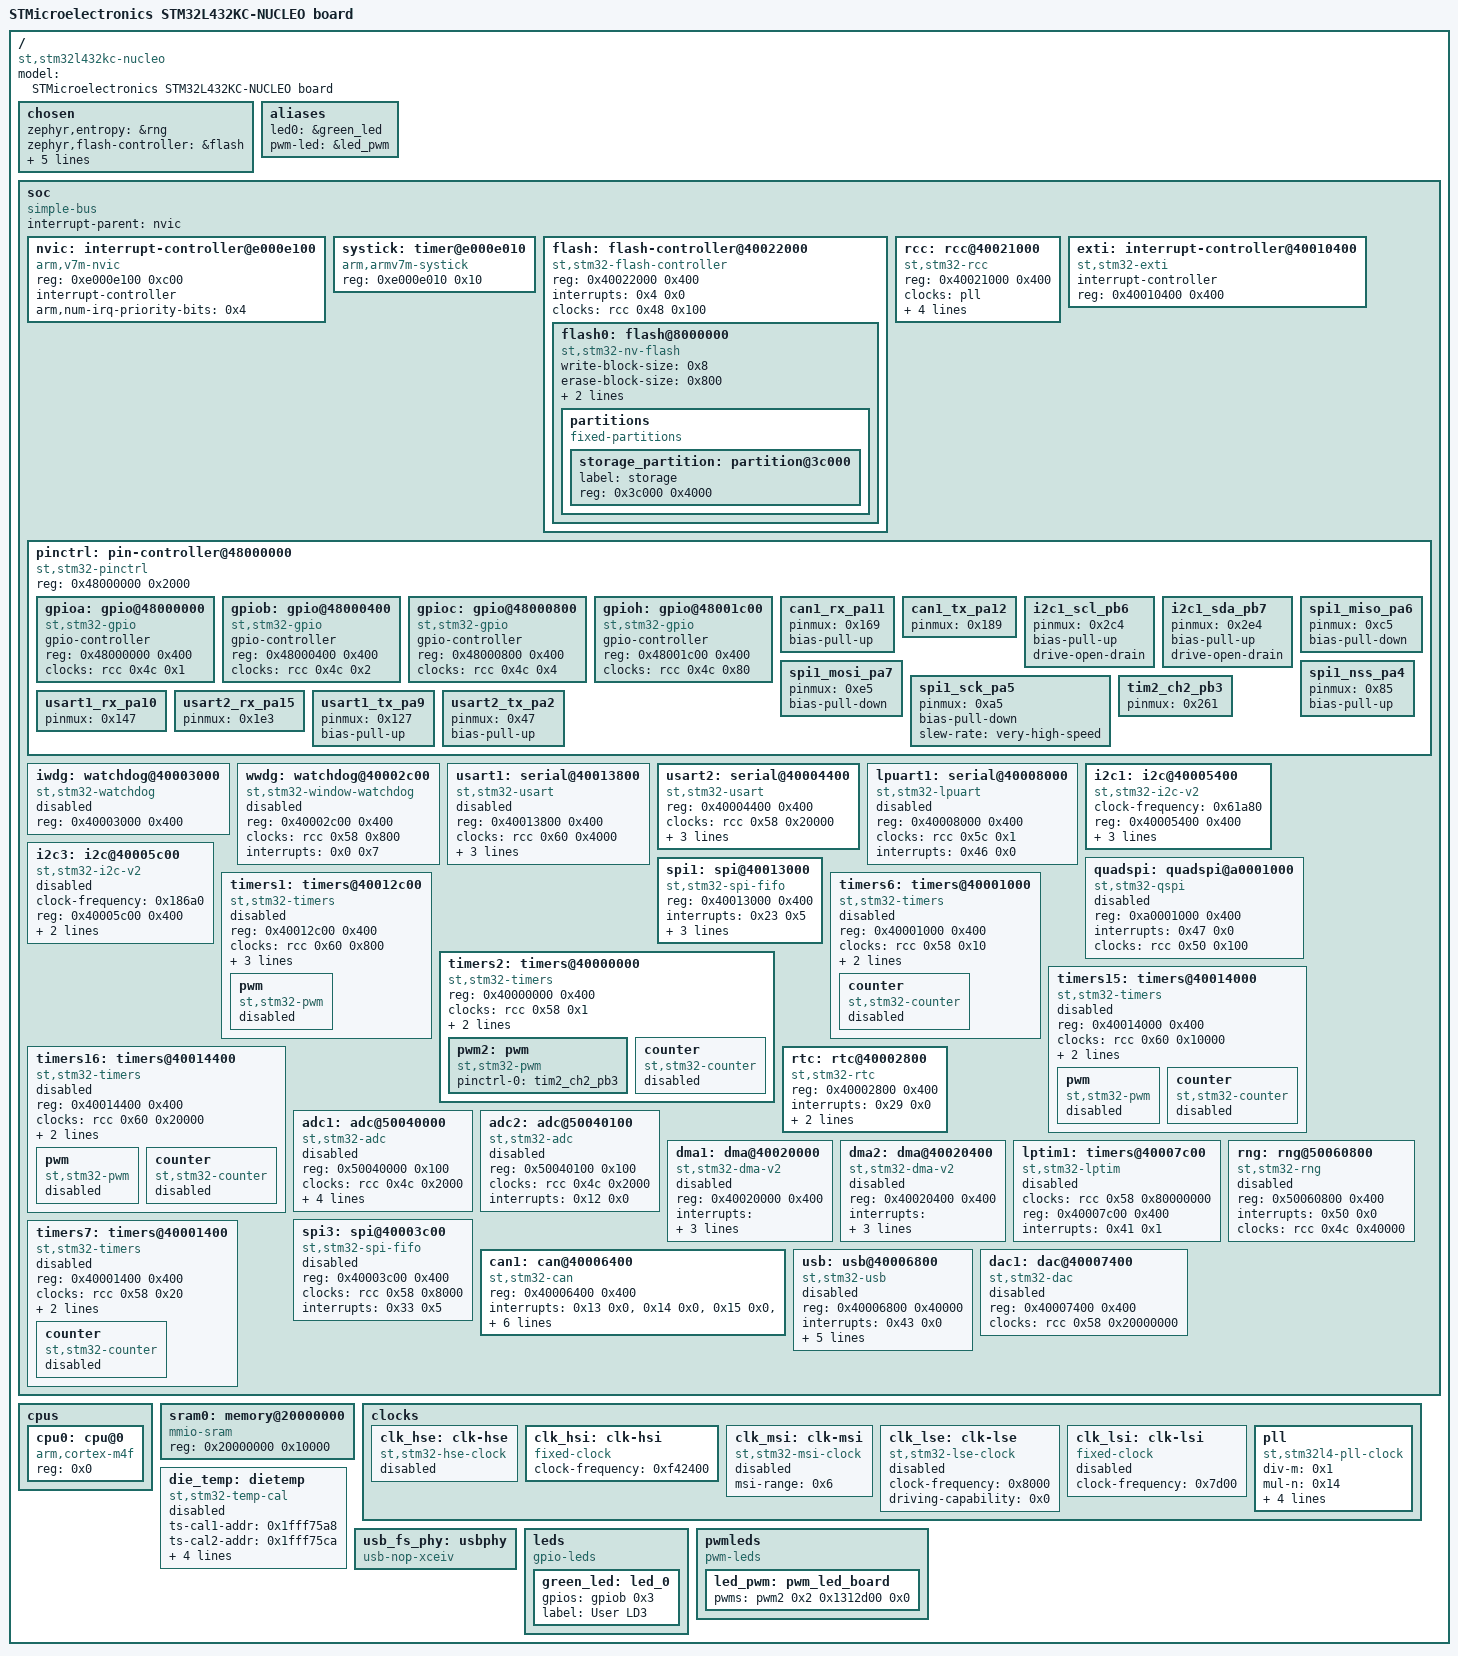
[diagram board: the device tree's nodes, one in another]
/dts-v1/;

/ {
	#address-cells = < 0x1 >;
	#size-cells = < 0x1 >;
	model = "STMicroelectronics STM32L432KC-NUCLEO board";
	compatible = "st,stm32l432kc-nucleo";
	chosen {
		zephyr,entropy = &rng;
		zephyr,flash-controller = &flash;
		zephyr,console = &usart2;
		zephyr,shell-uart = &usart2;
		zephyr,sram = &sram0;
		zephyr,flash = &flash0;
		zephyr,canbus = &can1;
	};
	aliases {
		led0 = &green_led;
		pwm-led = &led_pwm;
	};
	soc {
		#address-cells = < 0x1 >;
		#size-cells = < 0x1 >;
		compatible = "simple-bus";
		interrupt-parent = < &nvic >;
		ranges;
		nvic: interrupt-controller@e000e100 {
			#address-cells = < 0x1 >;
			compatible = "arm,v7m-nvic";
			reg = < 0xe000e100 0xc00 >;
			interrupt-controller;
			#interrupt-cells = < 0x2 >;
			arm,num-irq-priority-bits = < 0x4 >;
			phandle = < 0x1 >;
		};
		systick: timer@e000e010 {
			compatible = "arm,armv7m-systick";
			reg = < 0xe000e010 0x10 >;
		};
		flash: flash-controller@40022000 {
			compatible = "st,stm32-flash-controller", "st,stm32l4-flash-controller";
			reg = < 0x40022000 0x400 >;
			interrupts = < 0x4 0x0 >;
			clocks = < &rcc 0x48 0x100 >;
			#address-cells = < 0x1 >;
			#size-cells = < 0x1 >;
			flash0: flash@8000000 {
				compatible = "st,stm32-nv-flash", "soc-nv-flash";
				write-block-size = < 0x8 >;
				erase-block-size = < 0x800 >;
				max-erase-time = < 0x19 >;
				reg = < 0x8000000 0x40000 >;
				partitions {
					compatible = "fixed-partitions";
					#address-cells = < 0x1 >;
					#size-cells = < 0x1 >;
					storage_partition: partition@3c000 {
						label = "storage";
						reg = < 0x3c000 0x4000 >;
					};
				};
			};
		};
		rcc: rcc@40021000 {
			compatible = "st,stm32-rcc";
			#clock-cells = < 0x2 >;
			reg = < 0x40021000 0x400 >;
			clocks = < &pll >;
			clock-frequency = < 0x4c4b400 >;
			ahb-prescaler = < 0x1 >;
			apb1-prescaler = < 0x1 >;
			apb2-prescaler = < 0x1 >;
			phandle = < 0x2 >;
		};
		exti: interrupt-controller@40010400 {
			compatible = "st,stm32-exti";
			interrupt-controller;
			#interrupt-cells = < 0x1 >;
			reg = < 0x40010400 0x400 >;
		};
		pinctrl: pin-controller@48000000 {
			compatible = "st,stm32-pinctrl";
			#address-cells = < 0x1 >;
			#size-cells = < 0x1 >;
			reg = < 0x48000000 0x2000 >;
			gpioa: gpio@48000000 {
				compatible = "st,stm32-gpio";
				gpio-controller;
				#gpio-cells = < 0x2 >;
				reg = < 0x48000000 0x400 >;
				clocks = < &rcc 0x4c 0x1 >;
			};
			gpiob: gpio@48000400 {
				compatible = "st,stm32-gpio";
				gpio-controller;
				#gpio-cells = < 0x2 >;
				reg = < 0x48000400 0x400 >;
				clocks = < &rcc 0x4c 0x2 >;
				phandle = < 0x14 >;
			};
			gpioc: gpio@48000800 {
				compatible = "st,stm32-gpio";
				gpio-controller;
				#gpio-cells = < 0x2 >;
				reg = < 0x48000800 0x400 >;
				clocks = < &rcc 0x4c 0x4 >;
			};
			gpioh: gpio@48001c00 {
				compatible = "st,stm32-gpio";
				gpio-controller;
				#gpio-cells = < 0x2 >;
				reg = < 0x48001c00 0x400 >;
				clocks = < &rcc 0x4c 0x80 >;
			};
			can1_rx_pa11: can1_rx_pa11 {
				pinmux = < 0x169 >;
				bias-pull-up;
				phandle = < 0xf >;
			};
			can1_tx_pa12: can1_tx_pa12 {
				pinmux = < 0x189 >;
				phandle = < 0x10 >;
			};
			i2c1_scl_pb6: i2c1_scl_pb6 {
				pinmux = < 0x2c4 >;
				bias-pull-up;
				drive-open-drain;
				phandle = < 0x8 >;
			};
			i2c1_sda_pb7: i2c1_sda_pb7 {
				pinmux = < 0x2e4 >;
				bias-pull-up;
				drive-open-drain;
				phandle = < 0x9 >;
			};
			spi1_miso_pa6: spi1_miso_pa6 {
				pinmux = < 0xc5 >;
				bias-pull-down;
				phandle = < 0xc >;
			};
			spi1_mosi_pa7: spi1_mosi_pa7 {
				pinmux = < 0xe5 >;
				bias-pull-down;
				phandle = < 0xd >;
			};
			spi1_nss_pa4: spi1_nss_pa4 {
				pinmux = < 0x85 >;
				bias-pull-up;
				phandle = < 0xa >;
			};
			spi1_sck_pa5: spi1_sck_pa5 {
				pinmux = < 0xa5 >;
				bias-pull-down;
				slew-rate = "very-high-speed";
				phandle = < 0xb >;
			};
			tim2_ch2_pb3: tim2_ch2_pb3 {
				pinmux = < 0x261 >;
				phandle = < 0xe >;
			};
			usart1_rx_pa10: usart1_rx_pa10 {
				pinmux = < 0x147 >;
				phandle = < 0x5 >;
			};
			usart2_rx_pa15: usart2_rx_pa15 {
				pinmux = < 0x1e3 >;
				phandle = < 0x7 >;
			};
			usart1_tx_pa9: usart1_tx_pa9 {
				pinmux = < 0x127 >;
				bias-pull-up;
				phandle = < 0x4 >;
			};
			usart2_tx_pa2: usart2_tx_pa2 {
				pinmux = < 0x47 >;
				bias-pull-up;
				phandle = < 0x6 >;
			};
		};
		iwdg: watchdog@40003000 {
			compatible = "st,stm32-watchdog";
			reg = < 0x40003000 0x400 >;
			status = "disabled";
		};
		wwdg: watchdog@40002c00 {
			compatible = "st,stm32-window-watchdog";
			reg = < 0x40002c00 0x400 >;
			clocks = < &rcc 0x58 0x800 >;
			interrupts = < 0x0 0x7 >;
			status = "disabled";
		};
		usart1: serial@40013800 {
			compatible = "st,stm32-usart", "st,stm32-uart";
			reg = < 0x40013800 0x400 >;
			clocks = < &rcc 0x60 0x4000 >;
			interrupts = < 0x25 0x0 >;
			status = "disabled";
			pinctrl-0 = < &usart1_tx_pa9 &usart1_rx_pa10 >;
			pinctrl-names = "default";
			current-speed = < 0x1c200 >;
		};
		usart2: serial@40004400 {
			compatible = "st,stm32-usart", "st,stm32-uart";
			reg = < 0x40004400 0x400 >;
			clocks = < &rcc 0x58 0x20000 >;
			interrupts = < 0x26 0x0 >;
			status = "okay";
			pinctrl-0 = < &usart2_tx_pa2 &usart2_rx_pa15 >;
			pinctrl-names = "default";
			current-speed = < 0x1c200 >;
		};
		lpuart1: serial@40008000 {
			compatible = "st,stm32-lpuart", "st,stm32-uart";
			reg = < 0x40008000 0x400 >;
			clocks = < &rcc 0x5c 0x1 >;
			interrupts = < 0x46 0x0 >;
			status = "disabled";
		};
		i2c1: i2c@40005400 {
			compatible = "st,stm32-i2c-v2";
			clock-frequency = < 0x61a80 >;
			#address-cells = < 0x1 >;
			#size-cells = < 0x0 >;
			reg = < 0x40005400 0x400 >;
			clocks = < &rcc 0x58 0x200000 >;
			interrupts = < 0x1f 0x0 >, < 0x20 0x0 >;
			interrupt-names = "event", "error";
			status = "okay";
			pinctrl-0 = < &i2c1_scl_pb6 &i2c1_sda_pb7 >;
			pinctrl-names = "default";
		};
		i2c3: i2c@40005c00 {
			compatible = "st,stm32-i2c-v2";
			clock-frequency = < 0x186a0 >;
			#address-cells = < 0x1 >;
			#size-cells = < 0x0 >;
			reg = < 0x40005c00 0x400 >;
			clocks = < &rcc 0x58 0x800000 >;
			interrupts = < 0x48 0x0 >, < 0x49 0x0 >;
			interrupt-names = "event", "error";
			status = "disabled";
		};
		quadspi: quadspi@a0001000 {
			compatible = "st,stm32-qspi";
			#address-cells = < 0x1 >;
			#size-cells = < 0x0 >;
			reg = < 0xa0001000 0x400 >;
			interrupts = < 0x47 0x0 >;
			clocks = < &rcc 0x50 0x100 >;
			status = "disabled";
		};
		spi1: spi@40013000 {
			compatible = "st,stm32-spi-fifo", "st,stm32-spi";
			#address-cells = < 0x1 >;
			#size-cells = < 0x0 >;
			reg = < 0x40013000 0x400 >;
			interrupts = < 0x23 0x5 >;
			clocks = < &rcc 0x60 0x1000 >;
			status = "okay";
			pinctrl-0 = < &spi1_nss_pa4 &spi1_sck_pa5 &spi1_miso_pa6 &spi1_mosi_pa7 >;
			pinctrl-names = "default";
		};
		timers1: timers@40012c00 {
			compatible = "st,stm32-timers";
			reg = < 0x40012c00 0x400 >;
			clocks = < &rcc 0x60 0x800 >;
			interrupts = < 0x18 0x0 >, < 0x19 0x0 >, < 0x1a 0x0 >, < 0x1b 0x0 >;
			interrupt-names = "brk", "up", "trgcom", "cc";
			st,prescaler = < 0x0 >;
			status = "disabled";
			pwm {
				compatible = "st,stm32-pwm";
				status = "disabled";
				#pwm-cells = < 0x3 >;
			};
		};
		timers2: timers@40000000 {
			compatible = "st,stm32-timers";
			reg = < 0x40000000 0x400 >;
			clocks = < &rcc 0x58 0x1 >;
			interrupts = < 0x1c 0x0 >;
			interrupt-names = "global";
			st,prescaler = < 0x0 >;
			status = "okay";
			pwm2: pwm {
				compatible = "st,stm32-pwm";
				status = "okay";
				#pwm-cells = < 0x3 >;
				pinctrl-0 = < &tim2_ch2_pb3 >;
				pinctrl-names = "default";
				phandle = < 0x15 >;
			};
			counter {
				compatible = "st,stm32-counter";
				status = "disabled";
			};
		};
		timers6: timers@40001000 {
			compatible = "st,stm32-timers";
			reg = < 0x40001000 0x400 >;
			clocks = < &rcc 0x58 0x10 >;
			interrupts = < 0x36 0x0 >;
			interrupt-names = "global";
			st,prescaler = < 0x0 >;
			status = "disabled";
			counter {
				compatible = "st,stm32-counter";
				status = "disabled";
			};
		};
		timers15: timers@40014000 {
			compatible = "st,stm32-timers";
			reg = < 0x40014000 0x400 >;
			clocks = < &rcc 0x60 0x10000 >;
			interrupts = < 0x18 0x0 >;
			interrupt-names = "global";
			st,prescaler = < 0x0 >;
			status = "disabled";
			pwm {
				compatible = "st,stm32-pwm";
				status = "disabled";
				#pwm-cells = < 0x3 >;
			};
			counter {
				compatible = "st,stm32-counter";
				status = "disabled";
			};
		};
		timers16: timers@40014400 {
			compatible = "st,stm32-timers";
			reg = < 0x40014400 0x400 >;
			clocks = < &rcc 0x60 0x20000 >;
			interrupts = < 0x19 0x0 >;
			interrupt-names = "global";
			st,prescaler = < 0x0 >;
			status = "disabled";
			pwm {
				compatible = "st,stm32-pwm";
				status = "disabled";
				#pwm-cells = < 0x3 >;
			};
			counter {
				compatible = "st,stm32-counter";
				status = "disabled";
			};
		};
		rtc: rtc@40002800 {
			compatible = "st,stm32-rtc";
			reg = < 0x40002800 0x400 >;
			interrupts = < 0x29 0x0 >;
			clocks = < &rcc 0x58 0x10000000 >;
			prescaler = < 0x8000 >;
			status = "okay";
		};
		adc1: adc@50040000 {
			compatible = "st,stm32-adc";
			reg = < 0x50040000 0x100 >;
			clocks = < &rcc 0x4c 0x2000 >;
			interrupts = < 0x12 0x0 >;
			status = "disabled";
			vref-mv = < 0xbb8 >;
			#io-channel-cells = < 0x1 >;
			has-temp-channel;
			has-vref-channel;
			phandle = < 0x13 >;
		};
		adc2: adc@50040100 {
			compatible = "st,stm32-adc";
			reg = < 0x50040100 0x100 >;
			clocks = < &rcc 0x4c 0x2000 >;
			interrupts = < 0x12 0x0 >;
			status = "disabled";
			#io-channel-cells = < 0x1 >;
		};
		dma1: dma@40020000 {
			compatible = "st,stm32-dma-v2";
			#dma-cells = < 0x3 >;
			reg = < 0x40020000 0x400 >;
			interrupts = < 0xb 0x0 0xc 0x0 0xd 0x0 0xe 0x0 0xf 0x0 0x10 0x0 0x11 0x0 >;
			clocks = < &rcc 0x48 0x1 >;
			dma-requests = < 0x7 >;
			status = "disabled";
		};
		dma2: dma@40020400 {
			compatible = "st,stm32-dma-v2";
			#dma-cells = < 0x3 >;
			reg = < 0x40020400 0x400 >;
			interrupts = < 0x38 0x0 0x39 0x0 0x3a 0x0 0x3b 0x0 0x3c 0x0 0x44 0x0 0x45 0x0 >;
			clocks = < &rcc 0x48 0x2 >;
			dma-requests = < 0x7 >;
			status = "disabled";
		};
		lptim1: timers@40007c00 {
			compatible = "st,stm32-lptim";
			clocks = < &rcc 0x58 0x80000000 >;
			#address-cells = < 0x1 >;
			#size-cells = < 0x0 >;
			reg = < 0x40007c00 0x400 >;
			interrupts = < 0x41 0x1 >;
			interrupt-names = "wakeup";
			status = "disabled";
		};
		rng: rng@50060800 {
			compatible = "st,stm32-rng";
			reg = < 0x50060800 0x400 >;
			interrupts = < 0x50 0x0 >;
			clocks = < &rcc 0x4c 0x40000 >;
			status = "disabled";
		};
		spi3: spi@40003c00 {
			compatible = "st,stm32-spi-fifo", "st,stm32-spi";
			#address-cells = < 0x1 >;
			#size-cells = < 0x0 >;
			reg = < 0x40003c00 0x400 >;
			clocks = < &rcc 0x58 0x8000 >;
			interrupts = < 0x33 0x5 >;
			status = "disabled";
		};
		timers7: timers@40001400 {
			compatible = "st,stm32-timers";
			reg = < 0x40001400 0x400 >;
			clocks = < &rcc 0x58 0x20 >;
			interrupts = < 0x37 0x0 >;
			interrupt-names = "global";
			st,prescaler = < 0x0 >;
			status = "disabled";
			counter {
				compatible = "st,stm32-counter";
				status = "disabled";
			};
		};
		can1: can@40006400 {
			compatible = "st,stm32-can";
			reg = < 0x40006400 0x400 >;
			interrupts = < 0x13 0x0 >, < 0x14 0x0 >, < 0x15 0x0 >, < 0x16 0x0 >;
			interrupt-names = "TX", "RX0", "RX1", "SCE";
			clocks = < &rcc 0x58 0x2000000 >;
			status = "okay";
			sjw = < 0x1 >;
			sample-point = < 0x36b >;
			pinctrl-0 = < &can1_rx_pa11 &can1_tx_pa12 >;
			pinctrl-names = "default";
			bus-speed = < 0x1e848 >;
		};
		usb: usb@40006800 {
			compatible = "st,stm32-usb";
			reg = < 0x40006800 0x40000 >;
			interrupts = < 0x43 0x0 >;
			interrupt-names = "usb";
			num-bidir-endpoints = < 0x8 >;
			ram-size = < 0x400 >;
			maximum-speed = "full-speed";
			phys = < &usb_fs_phy >;
			clocks = < &rcc 0x58 0x4000000 >;
			status = "disabled";
		};
		dac1: dac@40007400 {
			compatible = "st,stm32-dac";
			reg = < 0x40007400 0x400 >;
			clocks = < &rcc 0x58 0x20000000 >;
			status = "disabled";
			#io-channel-cells = < 0x1 >;
		};
	};
	cpus {
		#address-cells = < 0x1 >;
		#size-cells = < 0x0 >;
		cpu0: cpu@0 {
			device_type = "cpu";
			compatible = "arm,cortex-m4f";
			reg = < 0x0 >;
		};
	};
	sram0: memory@20000000 {
		compatible = "mmio-sram";
		reg = < 0x20000000 0x10000 >;
	};
	clocks {
		clk_hse: clk-hse {
			#clock-cells = < 0x0 >;
			compatible = "st,stm32-hse-clock";
			status = "disabled";
		};
		clk_hsi: clk-hsi {
			#clock-cells = < 0x0 >;
			compatible = "fixed-clock";
			clock-frequency = < 0xf42400 >;
			status = "okay";
			phandle = < 0x12 >;
		};
		clk_msi: clk-msi {
			#clock-cells = < 0x0 >;
			compatible = "st,stm32-msi-clock";
			msi-range = < 0x6 >;
			status = "disabled";
		};
		clk_lse: clk-lse {
			#clock-cells = < 0x0 >;
			compatible = "st,stm32-lse-clock";
			clock-frequency = < 0x8000 >;
			driving-capability = < 0x0 >;
			status = "disabled";
		};
		clk_lsi: clk-lsi {
			#clock-cells = < 0x0 >;
			compatible = "fixed-clock";
			clock-frequency = < 0x7d00 >;
			status = "disabled";
		};
		pll: pll {
			#clock-cells = < 0x0 >;
			compatible = "st,stm32l4-pll-clock";
			status = "okay";
			div-m = < 0x1 >;
			mul-n = < 0x14 >;
			div-p = < 0x7 >;
			div-q = < 0x2 >;
			div-r = < 0x4 >;
			clocks = < &clk_hsi >;
			phandle = < 0x3 >;
		};
	};
	die_temp: dietemp {
		compatible = "st,stm32-temp-cal";
		ts-cal1-addr = < 0x1fff75a8 >;
		ts-cal2-addr = < 0x1fff75ca >;
		ts-cal1-temp = < 0x1e >;
		ts-cal2-temp = < 0x82 >;
		ts-cal-vrefanalog = < 0xbb8 >;
		io-channels = < &adc1 0x11 >;
		status = "disabled";
	};
	usb_fs_phy: usbphy {
		compatible = "usb-nop-xceiv";
		#phy-cells = < 0x0 >;
		phandle = < 0x11 >;
	};
	leds {
		compatible = "gpio-leds";
		green_led: led_0 {
			gpios = < &gpiob 0x3 0x0 >;
			label = "User LD3";
		};
	};
	pwmleds: pwmleds {
		compatible = "pwm-leds";
		status = "okay";
		led_pwm: pwm_led_board {
			pwms = < &pwm2 0x2 0x1312d00 0x0 >;
		};
	};
};
